# S1C31W74 register map
Vendor: Epson; Series: S1C31W74; File version: 1.11
CPU: CM0PLUS r0p1, little endian, MPU, no FPU, VTOR, 2 interrupt priority bits
Registers are 16-bit, read-write, reset 0x0 unless marked. A register's access mark holds for its fields unless they carry their own. Offsets are from the block's base; [hi:lo] are bit positions; 'fields as' and 'values as' point back to an identical list.

## SNDA — SNDA Sound generatior
Base 0x40000700
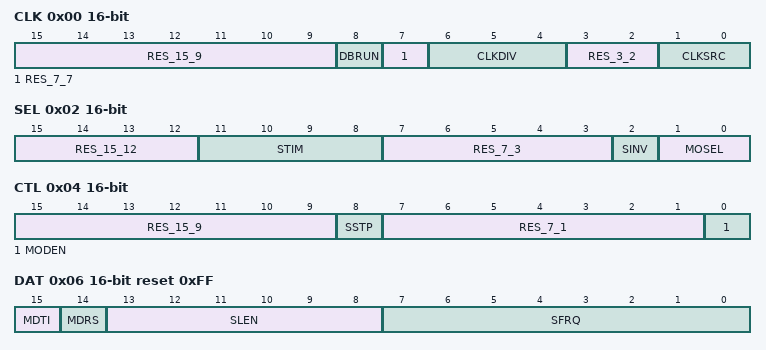
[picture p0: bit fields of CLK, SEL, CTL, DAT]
0x00 CLK — Clock Control Register
  [15:9] RES_15_9 ro — Reserved bits
  [8] DBRUN — Enable clock on debug mode
    0=DISABLE; 1=ENABLE
  [7] RES_7_7 ro — Reserved bits
  [6:4] CLKDIV — Clock division select
  [3:2] RES_3_2 ro — Reserved bits
  [1:0] CLKSRC — Clock source select
    0=IOSC; 1=OSC1; 2=OSC3; 3=EXOSC
0x02 SEL — SND Selection Register
  [15:12] RES_15_12 ro — Reserved bits
  [11:8] STIM — These bits select a tempo (when melody mode is selected) or a one-shot buzzer output duration (when one-shot buzzer mode is selected)
  [7:3] RES_7_3 ro — Reserved bits
  [2] SINV — Enable clock on debug mode
    0=DIRECT (Direct Drive mode); 1=NORMAL (Normal Drive mode)
  [1:0] MOSEL — These bits select a sound output mode
0x04 CTL — SND Control Register
  [15:9] RES_15_9 ro — Reserved bits
  [8] SSTP — Sound Stop control
  [7:1] RES_7_1 ro — Reserved bits
  [0] MODEN — This bit enables the SNDA operations
    0=DISABLE ((The operating clock is stopped); 1=ENABLE (The operating clock is supplied)
0x06 DAT reset 0xFF — SND Data Register
  [15] MDTI — Melody Tie Symbol
  [14] MDRS — Melody Reset Symbol
  [13:8] SLEN — Melody Note Symbol
  [7:0] SFRQ — Melody Frequency/Buzzer Frequency
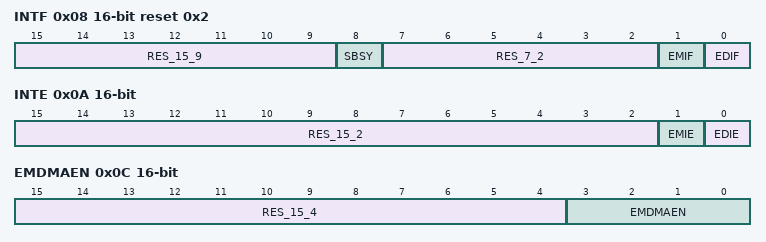
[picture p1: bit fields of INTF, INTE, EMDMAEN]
0x08 INTF reset 0x2 — SND Interrupt Flag Register
  [15:9] RES_15_9 ro — Reserved bits
  [8] SBSY ro — Sound Busy Status
  [7:2] RES_7_2 ro — Reserved bits
  [1] EMIF ro write-1-clears — Empty Interrupt Flag
    0=NOT_OCCURED (No cause of interrupt occurred); 1=OCCURED (Cause of interrupt occurred)
  [0] EDIF write-1-clears — END interrupt Flag
    values as EMIF
0x0A INTE — SND Interrupt Flag Register
  [15:2] RES_15_2 ro — Reserved bits
  [1] EMIE — Empty Interrupt Enable
    0=DISABLE (Interrupt Disable); 1=ENABLE (Interrupt Enable)
  [0] EDIE — END interrupt Enable
    0=DISABLE (Interrupt Disable); 1=ENABLE (Interrupt Enable)
0x0C EMDMAEN — Sound Buffer Empty DMA Request Enable Register
  [15:4] RES_15_4 ro — Reserved bits
  [3:0] EMDMAEN — These bits enable the SNDA to issue a DMA transfer request to the corresponding DMA controllerchannel when a sound buffer empty state has occurred.

## REMC2 — IR Remote Controller
Base 0x40000720
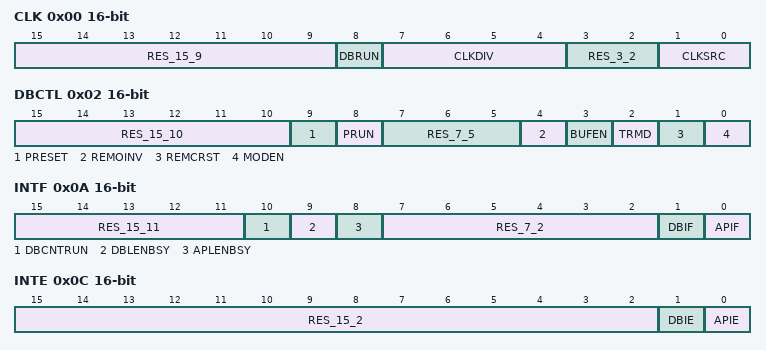
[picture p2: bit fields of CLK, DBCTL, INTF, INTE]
0x00 CLK — Clock Control Register
  [15:9] RES_15_9 ro — Reserved bits
  [8] DBRUN — Enable clock on debug mode
    0=DISABLE; 1=ENABLE
  [7:4] CLKDIV — Clock division select
  [3:2] RES_3_2 ro — Reserved bits
  [1:0] CLKSRC — Clock source select
    0=IOSC; 1=OSC1; 2=OSC3; 3=EXOSC
0x02 DBCTL — Data Bit Counter Control Register
  [15:10] RES_15_10 ro — Reserved bits
  [9] PRESET write-1-sets — Data bit counter reset (Cleared by writing to the REMCRST register bit)
    on write: 0=NON (No effect); 1=RESET | on read: 0=NORMAL (Resetting finished or normal operation); 1=BUSY (Resetting in progress)
  [8] PRUN — Data bit counter run/stop control (Cleared by writing to the REMCRST register bit)
    on write: 0=STOP (Stop counting); 1=RUN (Start counting) | on read: 0=STOP (Idle); 1=RUN (Counting)
  [7:5] RES_7_5 ro — Reserved bits
  [4] REMOINV — REMO invert
    0=NON_INVERT (Non-inverted); 1=INVERT (Inverted)
  [3] BUFEN — Buffer enable
    0=DISABLE; 1=ENABLE
  [2] TRMD — Data bit counter mode
    0=REPEAT (Repeat mode); 1=ONESHOT (One-shot mode)
  [1] REMCRST wo write-1-sets — Software Reset
    on write: 0=NON (No effect); 1=RESET (Issue software reset) | on read: 0=NORMAL (Software reset has finished (During normal operation)); 1=BUSY (Software reset is executing)
  [0] MODEN — REMC enable
    0=DISABLE; 1=ENABLE
0x04 DBCNT ro — Data Bit Counter Register (Cleared by writing to the REMCRST register bit)
  [15:0] DBCNT — Data bit counter
0x06 APLEN — Data bit Active Pulse Length Register
  [15:0] APLEN — Data bit active pulse length
0x08 DBLEN — Data Bit Length Register
  [15:0] DBLEN — Data bit length
0x0A INTF — Status / Interrupt Flag Register
  [15:11] RES_15_11 ro — Reserved bits
  [10] DBCNTRUN ro — Data bit counter running status (Cleared by writing to the REMCRST)
    0=IDLE; 1=RUN (Running (Counting))
  [9] DBLENBSY ro — DBLEN buffer busy
    0=READY (Transfer to the DBLEN buffer has completed); 1=BUSY (Transfer to the DBLEN buffer has not completed)
  [8] APLENBSY ro — APLEN buffer busy
    0=READY (Transfer to the APLEN buffer has completed); 1=BUSY (Transfer to the APLEN buffer has not completed)
  [7:2] RES_7_2 — Reserved bits
  [1] DBIF ro write-1-clears — Data bit length interrupt flag
    0=NOT_OCCURED (No cause of interrupt occurred); 1=OCCURED (Cause of interrupt occurred)
  [0] APIF ro write-1-clears — Data bit length first part interrupt flag (Cleared by writing to the REMCRST register bit or Cleared by writing 1)
    values as DBIF
0x0C INTE — Interrupt Enable Register
  [15:2] RES_15_2 ro — Reserved bits
  [1] DBIE — Data bit length interrupt enable
    0=DISABLE; 1=ENABLE
  [0] APIE — Data bit length first part interrupt enable
    0=DISABLE; 1=ENABLE
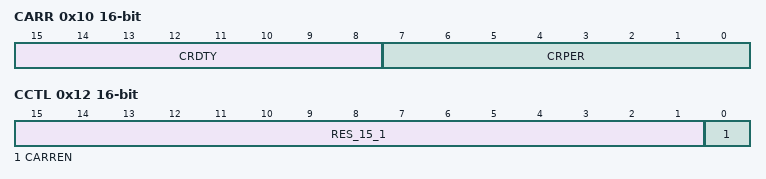
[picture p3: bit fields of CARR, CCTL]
0x10 CARR — Carrier Waveform Register
  [15:8] CRDTY — Carrier duty
  [7:0] CRPER — Carrier period
0x12 CCTL — Carrier Modulation Control Register
  [15:1] RES_15_1 ro — Reserved bits
  [0] CARREN — Carrier modulation enable
    0=DISABLE; 1=ENABLE
